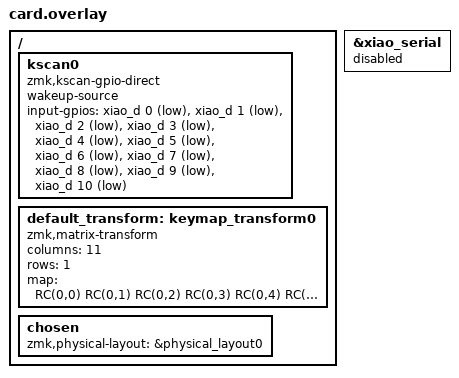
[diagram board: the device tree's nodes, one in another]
#include <dt-bindings/zmk/matrix_transform.h> // Put this with the other includes at the top of your overlay
#include "card-layouts.dtsi"

/ {
    kscan0: kscan0 {
        compatible = "zmk,kscan-gpio-direct";
        wakeup-source;

        input-gpios
            = <&xiao_d 0 (GPIO_ACTIVE_LOW | GPIO_PULL_UP)>
            , <&xiao_d 1 (GPIO_ACTIVE_LOW | GPIO_PULL_UP)>
            , <&xiao_d 2 (GPIO_ACTIVE_LOW | GPIO_PULL_UP)>
            , <&xiao_d 3 (GPIO_ACTIVE_LOW | GPIO_PULL_UP)>
            , <&xiao_d 4 (GPIO_ACTIVE_LOW | GPIO_PULL_UP)>
            , <&xiao_d 5 (GPIO_ACTIVE_LOW | GPIO_PULL_UP)>
            , <&xiao_d 6 (GPIO_ACTIVE_LOW | GPIO_PULL_UP)>
            , <&xiao_d 7 (GPIO_ACTIVE_LOW | GPIO_PULL_UP)>
            , <&xiao_d 8 (GPIO_ACTIVE_LOW | GPIO_PULL_UP)>
            , <&xiao_d 9 (GPIO_ACTIVE_LOW | GPIO_PULL_UP)>
            , <&xiao_d 10 (GPIO_ACTIVE_LOW | GPIO_PULL_UP)>
            ;

    };
};

&xiao_serial { status = "disabled"; };

/ {
    default_transform: keymap_transform0 {
        compatible = "zmk,matrix-transform";
        columns = <11>; // Length of the "col-gpios" array
        rows = <1>; // Length of the "row-gpios" array
        map = <
        
        RC(0,0) // R1
        RC(0,1) // R2
        RC(0,2) // B
        RC(0,3) // A
        RC(0,4) // RIGHT
        RC(0,5) // DOWN
        RC(0,6) // C
        RC(0,7) // L2
        RC(0,8) // LEFT
        RC(0,9) // UP
        RC(0,10) // L1
        
        >;
    };
};

/ {
    chosen {
        zmk,physical-layout = &physical_layout0;
        // zmk,matrix-transform = &default_transform;
        // Other chosen items
    };
};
